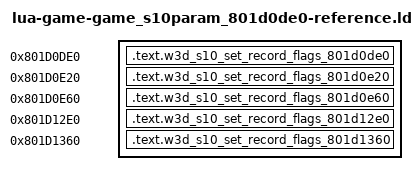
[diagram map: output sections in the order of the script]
/* Generated reference-only placements. All bodies are source-built. */
OUTPUT_FORMAT("elf32-powerpc")
OUTPUT_ARCH(powerpc)
ENTRY(w3d_s10_set_record_flags_801d0de0)
_SDA_BASE_ = 0x804b2540;
_SDA2_BASE_ = 0x804c2540;
SECTIONS {
  .text.w3d_s10_set_record_flags_801d0de0 0x801d0de0 : { *(.text.w3d_s10_set_record_flags_801d0de0) }
  .text.w3d_s10_set_record_flags_801d0e20 0x801d0e20 : { *(.text.w3d_s10_set_record_flags_801d0e20) }
  .text.w3d_s10_set_record_flags_801d0e60 0x801d0e60 : { *(.text.w3d_s10_set_record_flags_801d0e60) }
  .text.w3d_s10_set_record_flags_801d12e0 0x801d12e0 : { *(.text.w3d_s10_set_record_flags_801d12e0) }
  .text.w3d_s10_set_record_flags_801d1360 0x801d1360 : { *(.text.w3d_s10_set_record_flags_801d1360) }
  /DISCARD/ : { *(.text*) *(.rodata*) *(.data*) *(.bss*) *(.sdata*) *(.sbss*) *(.comment) }
}
